VERSION "1.0"

BS_:

BU_: VCU PCU BMS PDU

// ==================================================================
// 0x727: VCU → PCU CONTROL FRAME
// ==================================================================
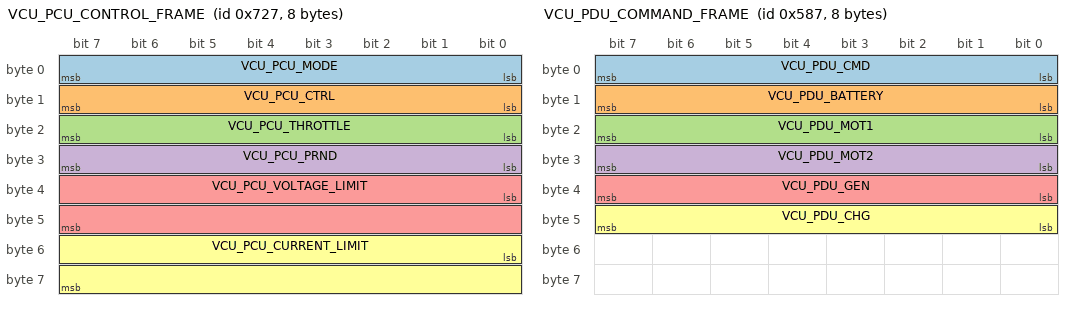
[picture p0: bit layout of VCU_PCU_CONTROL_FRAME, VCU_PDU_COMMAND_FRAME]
BO_ 1831 VCU_PCU_CONTROL_FRAME: 8 VCU
  SG_ VCU_PCU_MODE : 0|8@1+ (1,0) [0|255] "" PCU
  SG_ VCU_PCU_CTRL : 8|8@1+ (1,0) [0|255] "" PCU
  SG_ VCU_PCU_THROTTLE : 16|8@1+ (1,0) [0|100] "%" PCU
  SG_ VCU_PCU_PRND : 24|8@1+ (1,0) [0|255] "" PCU
  SG_ VCU_PCU_VOLTAGE_LIMIT : 32|16@1+ (1,0) [0|1000] "V" PCU
  SG_ VCU_PCU_CURRENT_LIMIT : 48|16@1+ (1,0) [0|1000] "A" PCU

VAL_ 1831 VCU_PCU_PRND 1 "Park" 2 "Reverse" 4 "Neutral" 8 "Drive";

// ==================================================================
// 0x20B: VCU → BMS COMMAND FRAME
// ==================================================================
BO_ 523 VCU_BMS_COMMAND_FRAME: 8 VCU
  SG_ VCU_BMS_CMD : 0|8@1+ (1,0) [0|255] "" BMS
  SG_ VCU_BMS_STATE_REQUEST : 8|8@1+ (1,0) [0|7] "" BMS

VAL_ 523 VCU_BMS_CMD 0 "NoCmd" 1 "SwitchOn" 2 "SwitchOff";
  0 "NoRequest" 1 "Idle" 2 "HV_Active" 3 "Charge" 4 "Fault_Shutdown";

// ==================================================================
// 0x587: VCU → PDU RELAY COMMAND FRAME
// ==================================================================
BO_ 1415 VCU_PDU_COMMAND_FRAME: 8 VCU
  SG_ VCU_PDU_CMD : 0|8@1+ (1,0) [0|1] "" PDU
  SG_ VCU_PDU_BATTERY : 8|8@1+ (1,0) [0|1] "" PDU
  SG_ VCU_PDU_MOT1 : 16|8@1+ (1,0) [0|1] "" PDU
  SG_ VCU_PDU_MOT2 : 24|8@1+ (1,0) [0|1] "" PDU
  SG_ VCU_PDU_GEN : 32|8@1+ (1,0) [0|1] "" PDU
  SG_ VCU_PDU_CHG : 40|8@1+ (1,0) [0|1] "" PDU

VAL_ 1415 VCU_PDU_CMD 0 "NoCmd" 1 "Switch";
VAL_ 1415 VCU_PDU_BATTERY 0 "Open" 1 "Close";
VAL_ 1415 VCU_PDU_MOT1 0 "Open" 1 "Close";
VAL_ 1415 VCU_PDU_MOT2 0 "Open" 1 "Close";
VAL_ 1415 VCU_PDU_GEN 0 "Open" 1 "Close";
VAL_ 1415 VCU_PDU_CHG 0 "Open" 1 "Close";
